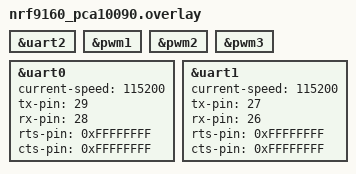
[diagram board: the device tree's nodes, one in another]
/* Needed to get NRF_UARTE2 and NRF_PWMn defined. */
&uart2 {
	status = "okay";
};

&pwm1 {
	status = "okay";
};

&pwm2 {
	status = "okay";
};

&pwm3 {
	status = "okay";
};

&uart0 {
	current-speed = <115200>;
	status = "okay";
	tx-pin = <29>;
	rx-pin = <28>;
	rts-pin = <0xFFFFFFFF>;
	cts-pin = <0xFFFFFFFF>;
};


&uart1 {
	status = "okay";
	current-speed = <115200>;
	tx-pin = <27>;
	rx-pin = <26>;
	rts-pin = <0xFFFFFFFF>;
	cts-pin = <0xFFFFFFFF>;
};
